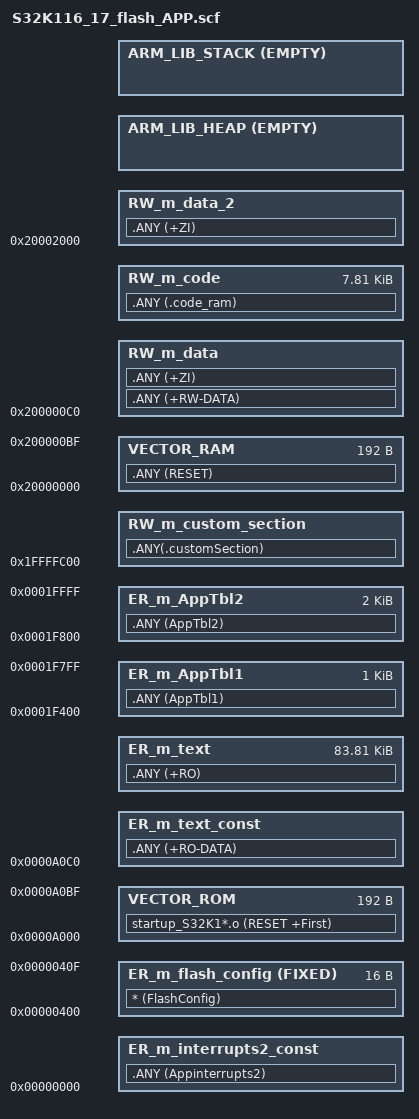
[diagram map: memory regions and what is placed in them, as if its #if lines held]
#! armcc -E
/*
#! armcc -E
#! armclang --target=arm-arm-none-eabi -xc -E
** ###################################################################
**     Processor:           S32K116 with 17 KB SRAM
**     Compiler:            ARM Compiler
**
**     Abstract:
**         Linker file for the ARM Compiler
**
**     Copyright (c) 2015-2016 Freescale Semiconductor, Inc.
**     Copyright 2017-2019 NXP
**     All rights reserved.
**
**     THIS SOFTWARE IS PROVIDED BY NXP "AS IS" AND ANY EXPRESSED OR
**     IMPLIED WARRANTIES, INCLUDING, BUT NOT LIMITED TO, THE IMPLIED WARRANTIES
**     OF MERCHANTABILITY AND FITNESS FOR A PARTICULAR PURPOSE ARE DISCLAIMED.
**     IN NO EVENT SHALL NXP OR ITS CONTRIBUTORS BE LIABLE FOR ANY DIRECT,
**     INDIRECT, INCIDENTAL, SPECIAL, EXEMPLARY, OR CONSEQUENTIAL DAMAGES
**     (INCLUDING, BUT NOT LIMITED TO, PROCUREMENT OF SUBSTITUTE GOODS OR
**     SERVICES; LOSS OF USE, DATA, OR PROFITS; OR BUSINESS INTERRUPTION)
**     HOWEVER CAUSED AND ON ANY THEORY OF LIABILITY, WHETHER IN CONTRACT,
**     STRICT LIABILITY, OR TORT (INCLUDING NEGLIGENCE OR OTHERWISE) ARISING
**     IN ANY WAY OUT OF THE USE OF THIS SOFTWARE, EVEN IF ADVISED OF
**     THE POSSIBILITY OF SUCH DAMAGE.
**
**     http:                 www.freescale.com
**     mail:                 support@freescale.com
**
** ###################################################################
*/

#if (defined(__ram_vector_table__))
  #define __ram_vector_table_size__    0x000000C0
#else
  #define __ram_vector_table_size__    0x00000000
#endif

/*
  0x00000000~0x0000A000->[40K]Bootloader区域
  0x0000A000~0x00020000->[88K]Application区域
      0x00000~0x00008->[   8B]interrupts2_rom 为了App能独立运行而添加，合成时将被Fbl覆盖
      0x0A000~0x0A0C0->[ 192B]interrupts_rom
      0x0A0C0~0x1F000->[83.8K]App代码区
      0x1F000~0x1FFFF->[   4K]App和Boot公共常量区,但所有权归App
*/
#define m_interrupts2_start            0x00000000
#define m_interrupts2_size             0x00000008

#define m_flash_config_start           0x00000400
#define m_flash_config_size            0x00000010

#define m_interrupts_start             0x0000A000
#define m_interrupts_size              0x000000C0

#define m_text_start                   0x0000A0C0   /* APP代码区 */
#define m_text_size                    (0x0001F000 - m_text_start)

#define m_AppTbl1_start                0x0001F400   /* APP数据区1(1K):存放APP的ROM表 */
#define m_AppTbl1_size                 (0x0001F800 - m_AppTbl1_start)

#define m_AppTbl2_start                0x0001F800   /* APP数据区2(2K):存放Appvalid标志,Boot将对此擦写 */
#define m_AppTbl2_size                 (0x00020000 - m_AppTbl2_start)

/*
  0x1FFFFC00~0x20000000->[ 1K]SRAM_L区域
  0x20000000~0x20003800->[14K]SRAM_U区域
      0x20000000~0x200000C0->[192B]interrupts_ram
      0x200000C0~0x20002000->[7.8K]data区域
      0x20002000~0x20003800->[ 6K] data_2区域
*/
#define m_interrupts_ram_start         0x20000000
#define m_interrupts_ram_size          0x000000C0

#define m_data_start                   0x200000C0
#define m_data_size                    (0x20002000 - m_data_start)

#define m_data_2_start                 0x20002000
#define m_data_2_size                  (0x20003800 - m_data_2_start)

#define m_custom_start                 0x1FFFFC00
#define m_custom_size                  0x00000400

/* Sizes */
#if (defined(__stack_size__))
  #define Stack_Size                   __stack_size__
#else
  #define Stack_Size                   0x0200
#endif

#if (defined(__heap_size__))
  #define Heap_Size                    __heap_size__
#else
  #define Heap_Size                    0x0200
#endif

LR_m_text m_text_start m_text_size
{ ; load region size_region
  ER_m_text_const m_text_start  { ; load address = execution address
    .ANY (+RO-DATA)
  }
  ER_m_text +0 m_text_size { ; load address = execution address
    .ANY (+RO)
  }

  VECTOR_RAM m_interrupts_ram_start m_interrupts_ram_size {
	 .ANY (RESET) 
  }
  RW_m_data m_data_start { ; RW data
   .ANY (+RW-DATA)
   .ANY (+ZI)
  }
  RW_m_code +0 m_data_size { ; RW data
   .ANY (.code_ram)
  }
  /* Custom Section Block that can be used to place data at absolute address. */
  /* Use __attribute__((section (".customSection"))) to place data here. */
  /* Use this section only when MTB (Micro Trace Buffer) is not used, because MTB uses the same RAM area, as described in S32K Reference Manual. */
  RW_m_custom_section m_custom_start ALIGN 0x4
  {
    .ANY(.customSection)  /* Keep section even if not referenced. */
  }
  RW_m_data_2 m_data_2_start m_data_2_size-Stack_Size-Heap_Size { ; RW data
    .ANY (+ZI)
  }
  ARM_LIB_HEAP ((ImageLimit(RW_m_data_2) == m_data_2_start) ? m_data_2_start : +0) EMPTY Heap_Size { ; Heap region growing up
  }
  ARM_LIB_STACK m_data_2_start+m_data_2_size EMPTY -Stack_Size { ; Stack region growing down
  }
}

LR_m_interrupts m_interrupts_start m_interrupts_size
{ ; load region size_region
  VECTOR_ROM m_interrupts_start m_interrupts_size 
  { ; load address = execution address
	 startup_S32K1*.o (RESET +First)
  }
}

LR_m_flash_config m_flash_config_start m_flash_config_size
{ ; load region size_region
  ER_m_flash_config m_flash_config_start FIXED m_flash_config_size { ; load address = execution address
    * (FlashConfig)
  }
}

LR_m_interrupts2 m_interrupts2_start m_interrupts2_size
{ ; load region size_region
  ER_m_interrupts2_const m_interrupts2_start  { ; load address = execution address
    .ANY (Appinterrupts2)
  }
}
LR_m_AppTbl1 m_AppTbl1_start m_AppTbl1_size
{ ; load region size_region
  ER_m_AppTbl1 m_AppTbl1_start m_AppTbl1_size { ; load address = execution address
    .ANY (AppTbl1)
  }
}
LR_m_AppTbl2 m_AppTbl2_start m_AppTbl2_size
{ ; load region size_region
  ER_m_AppTbl2 m_AppTbl2_start m_AppTbl2_size { ; load address = execution address
    .ANY (AppTbl2)
  }
}
